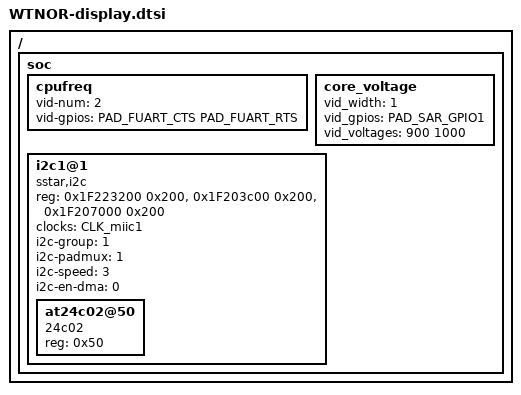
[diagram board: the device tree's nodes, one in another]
/*
* infinity2m-ssc011a-s01a-display.dtsi- Sigmastar
*
* Copyright (c) [2019~2020] SigmaStar Technology.
*
*
* This software is licensed under the terms of the GNU General Public
* License version 2, as published by the Free Software Foundation, and
* may be copied, distributed, and modified under those terms.
*
* This program is distributed in the hope that it will be useful,
* but WITHOUT ANY WARRANTY; without even the implied warranty of
* MERCHANTABILITY or FITNESS FOR A PARTICULAR PURPOSE.  See the
* GNU General Public License version 2 for more details.
*
*/

/ {
    soc {

        cpufreq {
            vid-num = /bits/ 8 <2>;
            vid-gpios = /bits/ 8 <PAD_FUART_CTS PAD_FUART_RTS>;
        };
		core_voltage {
            vid_width = <1>;
            vid_gpios = <PAD_SAR_GPIO1>;
            vid_voltages = <900 1000>;  //2b'00 2b'01
        };
        i2c1@1{
            compatible = "sstar,i2c";
            reg = <0x1F223200 0x200>,<0x1F203c00 0x200>,<0x1F207000 0x200>;
                #address-cells = <1>;
                #size-cells = <0>;
            clocks = <&CLK_miic1>;
            i2c-group = <1>;
            /*
             * padmux: 1 -> PAD_GPIO2, PAD_GPIO3
             *         2 -> PAD_HDMITX_SCL, PAD_HDMITX_SDA
             *         4 -> PAD_TTL22, PAD_TTL23
             *         5 -> PAD_SD_CLK, PAD_SD_CMD
            */
            i2c-padmux = <1>;
            /*
              *  speed: 0 -> HWI2C_HIGH(high speed: 400 KHz)
              *         1 -> HWI2C_NORMAL(normal speed: 300 KHz)
              *         2 -> HWI2C_SLOW(slow speed: 200 KHz)
              *         3 -> HWI2C_VSLOW(very slow: 100 KHz)
              *         4 -> HWI2C_USLOW(ultra slow: 50 KHz)
              *         5 -> HWI2C_UVSLOW(ultra-very slow: 25 KHz)
              */
            i2c-speed = <3>;
            i2c-en-dma = <0>;  // 0: disable; 1: enable;
            status = "ok";
            at24c02@50{ //EVB i2c-padmux=2 SSD201_SZ_DEMO_BOARD i2c-padmux=1
                compatible = "24c02";
                reg = <0x50>;
			};
		};
	};
};
